# GD32F1x0 register map
File version: 1.0
CPU: CM3 r2p1, little endian, no MPU, no FPU, 4 interrupt priority bits
Registers are 32-bit, read-write, reset 0x0 unless marked. A register's access mark holds for its fields unless they carry their own. Offsets are from the block's base; [hi:lo] are bit positions.

## RCU — Reset and clock unit
Base 0x40021000
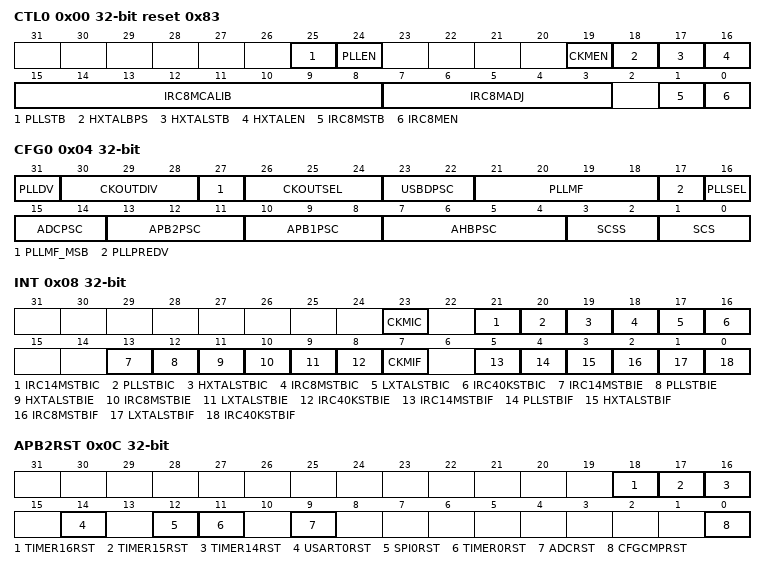
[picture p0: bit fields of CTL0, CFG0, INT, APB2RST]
0x00 CTL0 access per field reset 0x83 — Control register 0
  [25] PLLSTB ro — PLL Clock Stabilization Flag
  [24] PLLEN rw — PLL enable
  [19] CKMEN rw — HXTAL Clock Monitor Enable
  [18] HXTALBPS rw — External crystal oscillator (HXTAL) clock bypass mode enable
  [17] HXTALSTB ro — External crystal oscillator (HXTAL) clock stabilization flag
  [16] HXTALEN rw — External High Speed oscillator Enable
  [15:8] IRC8MCALIB ro — High Speed Internal Oscillator calibration value register
  [7:3] IRC8MADJ rw — High Speed Internal Oscillator clock trim adjust value
  [1] IRC8MSTB ro — IRC8M High Speed Internal Oscillator stabilization Flag
  [0] IRC8MEN rw — Internal High Speed oscillator Enable
0x04 CFG0 access per field — Clock configuration register 0 (RCU_CFG0)
  [31] PLLDV rw — The CK_PLL divide by 1 or 2 for CK_OUT
  [30:28] CKOUTDIV rw — The CK_OUT divider which the CK_OUT frequency can be reduced
  [27] PLLMF_MSB rw — Bit 4 of PLLMF register
  [26:24] CKOUTSEL rw — CK_OUT Clock Source Selection
  [23:22] USBDPSC rw — USBD clock prescaler selection
  [21:18] PLLMF rw — PLL multiply factor
  [17] PLLPREDV rw — HXTAL divider for PLL source clock selection.
  [16] PLLSEL rw — PLL Clock Source Selection
  [15:14] ADCPSC rw — ADC clock prescaler selection
  [13:11] APB2PSC rw — APB2 prescaler selection
  [10:8] APB1PSC rw — APB1 prescaler selection
  [7:4] AHBPSC rw — AHB prescaler selection
  [3:2] SCSS ro — System clock switch status
  [1:0] SCS rw — System clock switch
0x08 INT access per field — Clock interrupt register (RCU_INT)
  [23] CKMIC wo — HXTAL Clock Stuck Interrupt Clear
  [21] IRC14MSTBIC wo — IRC14M stabilization Interrupt Clear
  [20] PLLSTBIC wo — PLL stabilization Interrupt Clear
  [19] HXTALSTBIC wo — HXTAL Stabilization Interrupt Clear
  [18] IRC8MSTBIC wo — IRC8M Stabilization Interrupt Clear
  [17] LXTALSTBIC wo — LXTAL Stabilization Interrupt Clear
  [16] IRC40KSTBIC wo — IRC40K Stabilization Interrupt Clear
  [13] IRC14MSTBIE rw — IRC14M Stabilization Interrupt Enable
  [12] PLLSTBIE rw — PLL Stabilization Interrupt Enable
  [11] HXTALSTBIE rw — HXTAL Stabilization Interrupt Enable
  [10] IRC8MSTBIE rw — IRC8M Stabilization Interrupt Enable
  [9] LXTALSTBIE rw — LXTAL Stabilization Interrupt Enable
  [8] IRC40KSTBIE rw — IRC40K Stabilization interrupt enable
  [7] CKMIF ro — HXTAL Clock Stuck Interrupt Flag
  [5] IRC14MSTBIF ro — IRC14M stabilization interrupt flag
  [4] PLLSTBIF ro — PLL stabilization interrupt flag
  [3] HXTALSTBIF ro — HXTAL stabilization interrupt flag
  [2] IRC8MSTBIF ro — IRC8M stabilization interrupt flag
  [1] LXTALSTBIF ro — LXTAL stabilization interrupt flag
  [0] IRC40KSTBIF ro — IRC40K stabilization interrupt flag
0x0C APB2RST — APB2 reset register (RCU_APB2RST)
  [18] TIMER16RST — TIMER16 reset
  [17] TIMER15RST — TIMER15 reset
  [16] TIMER14RST — TIMER14 reset
  [14] USART0RST — USART0 Reset
  [12] SPI0RST — SPI0 Reset
  [11] TIMER0RST — TIMER0 reset
  [9] ADCRST — ADC reset
  [0] CFGCMPRST — System configuration and comparator reset
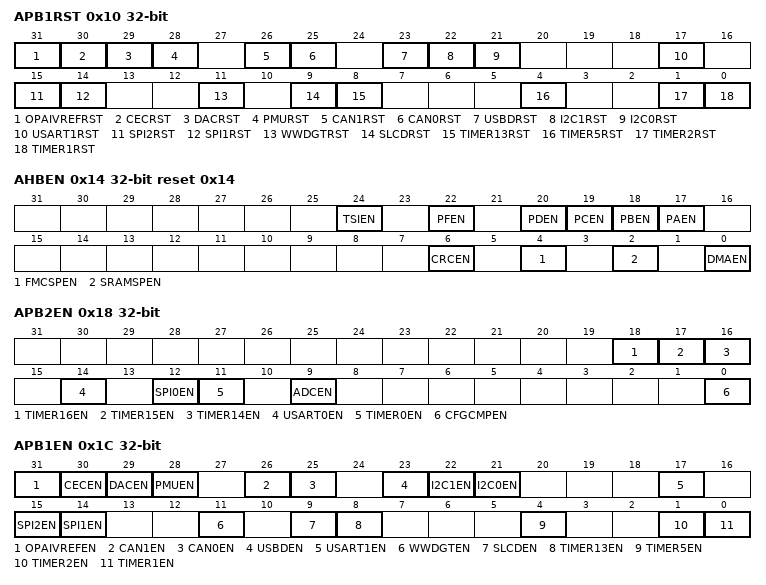
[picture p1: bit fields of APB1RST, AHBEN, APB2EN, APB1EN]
0x10 APB1RST — APB1 reset register (RCU_APB1RST)
  [31] OPAIVREFRST — OPA and IVREF reset
  [30] CECRST — HDMI CEC reset
  [29] DACRST — DAC reset
  [28] PMURST — Power control reset
  [26] CAN1RST — CAN1 reset
  [25] CAN0RST — CAN0 reset
  [23] USBDRST — USBD reset
  [22] I2C1RST — I2C1 reset
  [21] I2C0RST — I2C0 reset
  [17] USART1RST — USART1 reset
  [15] SPI2RST — SPI2 reset
  [14] SPI1RST — SPI1 reset
  [11] WWDGTRST — Window watchdog timer reset
  [9] SLCDRST — SLCD reset
  [8] TIMER13RST — TIMER13 timer reset
  [4] TIMER5RST — TIMER5 timer reset
  [1] TIMER2RST — TIMER2 timer reset
  [0] TIMER1RST — TIMER1 timer reset
0x14 AHBEN reset 0x14 — AHB enable register (RCU_AHBEN)
  [24] TSIEN — TSI clock enable
  [22] PFEN — GPIO port F clock enable
  [20] PDEN — GPIO port D clock enable
  [19] PCEN — GPIO port C clock enable
  [18] PBEN — GPIO port B clock enable
  [17] PAEN — GPIO port A clock enable
  [6] CRCEN — CRC clock enable
  [4] FMCSPEN — FMC clock enable
  [2] SRAMSPEN — SRAM interface clock enable
  [0] DMAEN — DMA clock enable
0x18 APB2EN — APB2 enable register (RCU_APB2EN)
  [18] TIMER16EN — TIMER16 timer clock enable
  [17] TIMER15EN — TIMER15 timer clock enable
  [16] TIMER14EN — TIMER14 timer clock enable
  [14] USART0EN — USART0 clock enable
  [12] SPI0EN — SPI0 clock enable
  [11] TIMER0EN — TIMER0 timer clock enable
  [9] ADCEN — ADC interface clock enable
  [0] CFGCMPEN — System configuration and comparator clock enable
0x1C APB1EN — APB1 enable register (RCU_APB1EN)
  [31] OPAIVREFEN — OPA and IVREF clock enable
  [30] CECEN — HDMI CEC interface clock enable
  [29] DACEN — DAC interface clock enable
  [28] PMUEN — Power interface clock enable
  [26] CAN1EN — CAN1 clock enable
  [25] CAN0EN — CAN0 clock enable
  [23] USBDEN — USBD clock enable
  [22] I2C1EN — I2C1 clock enable
  [21] I2C0EN — I2C0 clock enable
  [17] USART1EN — USART1 clock enable
  [15] SPI2EN — SPI2 clock enable
  [14] SPI1EN — SPI1 clock enable
  [11] WWDGTEN — Window watchdog timer clock enable
  [9] SLCDEN — SLCD clock enable
  [8] TIMER13EN — TIMER13 timer clock enable
  [4] TIMER5EN — TIMER5 timer clock enable
  [1] TIMER2EN — TIMER2 timer clock enable
  [0] TIMER1EN — TIMER1 timer clock enable
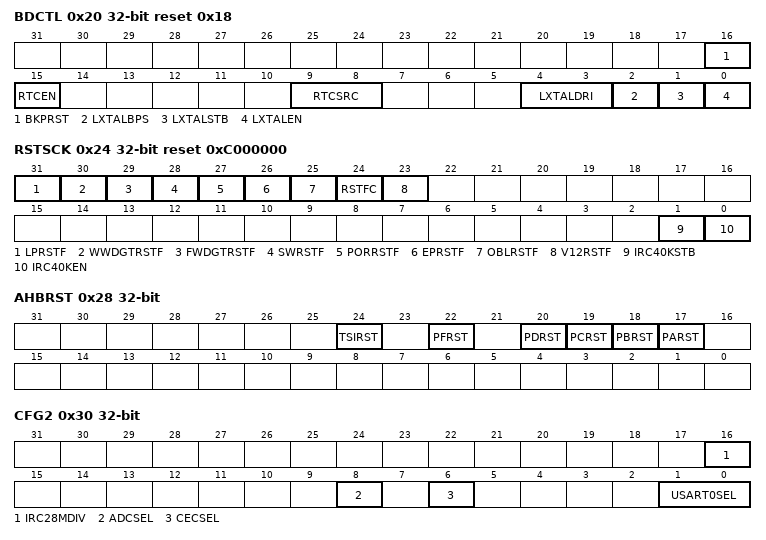
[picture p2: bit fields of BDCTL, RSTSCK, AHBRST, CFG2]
0x20 BDCTL access per field reset 0x18 — Backup domain control register (RCU_BDCTL)
  [16] BKPRST rw — Backup domain reset
  [15] RTCEN rw — RTC clock enable
  [9:8] RTCSRC rw — RTC clock entry selection
  [4:3] LXTALDRI rw — LXTAL drive capability
  [2] LXTALBPS rw — LXTAL bypass mode enable
  [1] LXTALSTB ro — External low-speed oscillator stabilization
  [0] LXTALEN rw — LXTAL enable
0x24 RSTSCK access per field reset 0xC000000 — Reset source /clock register (RCU_RSTSCK)
  [31] LPRSTF rw — Low-power reset flag
  [30] WWDGTRSTF rw — Window watchdog timer reset flag
  [29] FWDGTRSTF rw — Free Watchdog timer reset flag
  [28] SWRSTF rw — Software reset flag
  [27] PORRSTF rw — Power reset flag
  [26] EPRSTF rw — External PIN reset flag
  [25] OBLRSTF rw — Option byte loader reset flag
  [24] RSTFC rw — Reset flag clear
  [23] V12RSTF rw — V12 domain Power reset flag
  [1] IRC40KSTB ro — IRC40K stabilization
  [0] IRC40KEN rw — IRC40K enable
0x28 AHBRST — AHB reset register
  [24] TSIRST — TSI unit reset
  [22] PFRST — GPIO port F reset
  [20] PDRST — GPIO port D reset
  [19] PCRST — GPIO port C reset
  [18] PBRST — GPIO port B reset
  [17] PARST — GPIO port A reset
0x2C CFG1 — Configuration register 1
  [3:0] HXTALPREDV — CK_HXTAL divider previous PLL
0x30 CFG2 — Configuration register 2
  [16] IRC28MDIV — CK_IRC28M divider 2 or not
  [8] ADCSEL — CK_ADC clock source selection
  [6] CECSEL — CK_CEC clock source selection
  [1:0] USART0SEL — CK_USART0 clock source selection
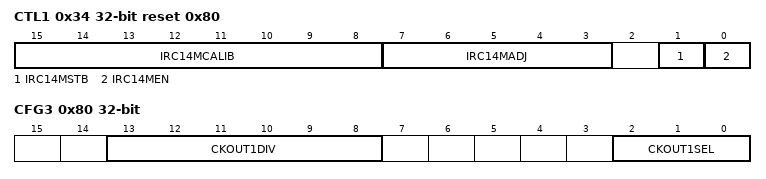
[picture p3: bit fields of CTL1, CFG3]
0x34 CTL1 access per field reset 0x80 — Control register 1
  [15:8] IRC14MCALIB ro — Internal 14M RC Oscillator calibration value register
  [7:3] IRC14MADJ rw — Internal 14M RC Oscillator clock trim adjust value
  [1] IRC14MSTB ro — IRC14M Internal 14M RC Oscillator stabilization Flag
  [0] IRC14MEN rw — IRC14M Internal 14M RC oscillator Enable
0x80 CFG3 — Configuration register 4
  [13:8] CKOUT1DIV — The CK_OUT1 divider which the CK_OUT1 frequency can be reduced see bits 2:0 of RCU_CFG3 for CK_OUT1
  [2:0] CKOUT1SEL — CKOUT1 Clock Source Selection
0xF8 ADDAPB1EN — Additional enable register
  [0] I2C2EN — I2C2 unit clock enable
0xFC ADDAPB1RST — Additional reset register
  [0] I2C2RST — I2C2 unit reset
0x100 VKEY wo — Voltage key register
  [31:0] KEY — The key of RCU_PDVSEL and RCU_DSV register
0x134 DSV — Deep-sleep mode voltage register
  [2:0] DSLPVS — Deep-sleep mode voltage select
0x138 PDVSEL — Power down voltage select register
  [0] PDRVS — Power down voltage select
